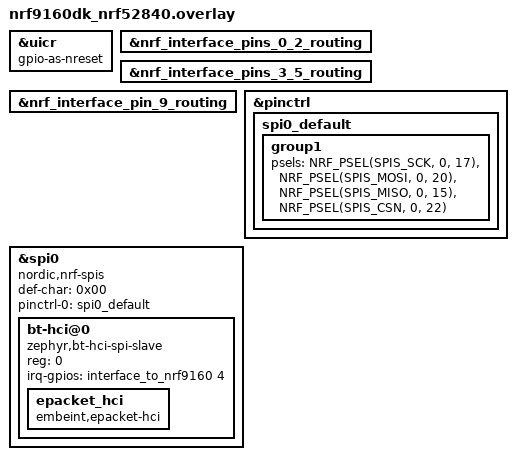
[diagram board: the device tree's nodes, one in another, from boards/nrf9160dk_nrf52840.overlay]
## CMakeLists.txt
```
# SPDX-License-Identifier: Apache-2.0

cmake_minimum_required(VERSION 3.20.0)
find_package(Zephyr REQUIRED HINTS $ENV{ZEPHYR_BASE})
project(hci_spi)

FILE(GLOB app_sources src/*.c)
target_sources(app PRIVATE ${app_sources})
```

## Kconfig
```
# Firmware update values

config INFUSE_APPLICATION_ID
	hex "Unique application identifier"
	default 0xB7000001

configdefault IMG_MANAGER
	default y

configdefault INFUSE_CPATCH
	default y if BOOTLOADER_MCUBOOT

config HEAP_MEM_POOL_ADD_SIZE_HCI_IPC
	int "Heap size required by IPC library"
	depends on DT_HAS_ZEPHYR_BT_HCI_IPC_ENABLED
	default 4096

# Reduced RAM footprint on memory constrained platforms
configdefault BT_MAX_CONN
	default 4 if SOC_NRF54L05
	default 4 if SOC_NRF52832
	default 8 if SOC_NRF52833
	default 16

configdefault BT_EXT_ADV_MAX_ADV_SET
	default 2 if SOC_NRF54L05
	default 4 if SOC_NRF52832
	default 6

# Softdevice default values

configdefault BT_CTLR_SDC_PERIPHERAL_COUNT
	default 3

configdefault BT_CTLR_SDC_SCAN_BUFFER_COUNT
	default 5

configdefault BT_CTLR_SDC_TX_PACKET_COUNT
	default 5

configdefault BT_CTLR_SDC_RX_PACKET_COUNT
	default 5

# No logging or console output on ROM constrained platforms
if SOC_NRF54L05

configdefault LOG
	default n

configdefault PRINTK
	default n

configdefault BOOT_BANNER
	default n

configdefault EARLY_CONSOLE
	default n

configdefault STDOUT_CONSOLE
	default n

endif # SOC_NRF54L05

# Channel Sounding (only available on SoCs with radio support)
configdefault BT_CTLR_CHANNEL_SOUNDING
	default y

configdefault BT_CTLR_CHANNEL_SOUNDING_TEST
	default n if SOC_NRF54L05

source "Kconfig.zephyr"
```

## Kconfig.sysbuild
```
# ECDSA-P256 verification is smaller than RSA-2048 in MCUboot
choice BOOT_SIGNATURE_TYPE
	default BOOT_SIGNATURE_TYPE_ECDSA_P256 if "$(BOARD_QUALIFIERS)" = "nrf54l05/cpuapp"
endchoice

config INFUSE_MCUBOOT_MULTITHREADING
	default n if "$(BOARD_QUALIFIERS)" = "nrf54l05/cpuapp"

source "share/sysbuild/Kconfig"
```

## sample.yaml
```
sample:
  description: Allows Zephyr to provide Bluetooth connectivity via SPI.
  name: Bluetooth HCI SPI
common:
  tags:
    - app
    - cpatch
    - epacket
    - kv_store
    - rpc
  harness: bluetooth
  filter: dt_compat_enabled("zephyr,bt-hci-spi-slave")
  integration_platforms:
    - auroch@1.0.0/nrf54l15/cpuapp
    - tauro2/nrf54l15/cpuapp
    - tauro/nrf52840
  platform_exclude:
    - nrf9160dk@0.7.0/nrf52840
tests:
  sample.bluetooth.hci_spi:
    sysbuild: false
    integration_platforms:
      - thingy91x/nrf5340/cpuapp
  sample.bluetooth.hci_spi.sysbuild:
    sysbuild: true
    integration_platforms:
      - thingy91x/nrf5340/cpuapp
      - nrf54l15dk/nrf54l05/cpuapp
  sample.bluetooth.hci_spi.infuse:
    filter: dt_compat_enabled("zephyr,bt-hci-spi-slave") and not CONFIG_SOC_NRF5340_CPUAPP
    required_snippets:
      - infuse-bt-ctlr
    sysbuild: false
  sample.bluetooth.hci_spi.sysbuild.infuse:
    filter: dt_compat_enabled("zephyr,bt-hci-spi-slave") and not CONFIG_SOC_NRF5340_CPUAPP
    required_snippets:
      - infuse-bt-ctlr
    sysbuild: true
```

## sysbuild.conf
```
SB_CONFIG_INFUSE_INTEGRATION=y
SB_CONFIG_INFUSE_INTEGRATION_BT_CTLR=y
```

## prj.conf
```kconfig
CONFIG_GPIO=y
CONFIG_SPI=y
CONFIG_SPI_PERIPHERAL=y
CONFIG_MAIN_STACK_SIZE=1024
CONFIG_BT=y
CONFIG_BT_HCI_RAW=y

# Flash operations for DFU
CONFIG_FLASH=y
CONFIG_FLASH_MAP=y
CONFIG_STREAM_FLASH=y
CONFIG_CRC=y

# Infuse-IoT Bluetooth defaults
CONFIG_INFUSE_SDK_BLUETOOTH=y

# RPC commands
CONFIG_INFUSE_RPC=y
CONFIG_INFUSE_RPC_COMMAND_APPLICATION_INFO=y
CONFIG_INFUSE_RPC_COMMAND_FILE_WRITE_BASIC=y

# Infuse-IoT ePacket
CONFIG_NET_BUF_POOL_USAGE=y
CONFIG_EPACKET=y
CONFIG_EPACKET_BUFFERS_RX=5

# Output the .lst file
CONFIG_OUTPUT_DISASSEMBLY=y
```

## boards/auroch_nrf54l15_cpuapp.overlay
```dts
#include "nordic_sdc.dtsi"
```

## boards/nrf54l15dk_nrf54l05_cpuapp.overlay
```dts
#include "nordic_sdc.dtsi"

&pinctrl {
	spi21_default: spi21_default {
		group1 {
			psels = <NRF_PSEL(SPIS_SCK, 1, 11)>,
				<NRF_PSEL(SPIS_MOSI, 1, 12)>,
				<NRF_PSEL(SPIS_MISO, 1, 15)>,
				<NRF_PSEL(SPIS_CSN, 1, 16)>;
		};
	};
};

&spi21 {
	compatible = "nordic,nrf-spis";
	status = "okay";
	def-char = <0x00>;
	pinctrl-0 = <&spi21_default>;
	pinctrl-names = "default";
	/delete-property/rx-delay-supported;
	/delete-property/rx-delay;

	wake-gpios = <&gpio0 2 GPIO_ACTIVE_HIGH>;

	hci_spi: bt-hci@0 {
		compatible = "zephyr,bt-hci-spi-slave";
		reg = <0>;
		irq-gpios = <&gpio0 3 GPIO_ACTIVE_HIGH>;
	};
};

/* External flash is unused */
&mx25r64 {
	status = "disabled";
};
```

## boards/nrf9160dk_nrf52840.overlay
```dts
/*
 * Copyright (c) 2024 Embeint Holdings Pty Ltd
 *
 * SPDX-License-Identifier: Apache-2.0
 */

&uicr {
	gpio-as-nreset;
};

/* Route pins through for SPI */
&nrf_interface_pins_0_2_routing {
	status = "okay";
};
&nrf_interface_pins_3_5_routing {
	status = "okay";
};
&nrf_interface_pin_9_routing {
	status = "okay";
};

&pinctrl {
	/* nRF9160 interface pins */
	spi0_default: spi0_default {
		group1 {
			psels = <NRF_PSEL(SPIS_SCK, 0, 17)>,
				<NRF_PSEL(SPIS_MOSI, 0, 20)>,
				<NRF_PSEL(SPIS_MISO, 0, 15)>,
				<NRF_PSEL(SPIS_CSN, 0, 22)>;
		};
	};
};

&spi0 {
	compatible = "nordic,nrf-spis";
	status = "okay";
	def-char = <0x00>;
	pinctrl-0 = <&spi0_default>;
	pinctrl-names = "default";

	bt-hci@0 {
		compatible = "zephyr,bt-hci-spi-slave";
		reg = <0>;
		irq-gpios = <&interface_to_nrf9160 4 GPIO_ACTIVE_HIGH>;
		epacket_hci: epacket_hci {
			compatible = "embeint,epacket-hci";
		};
	};
};

#include "nordic_sdc.dtsi"
```

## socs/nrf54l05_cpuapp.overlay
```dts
/*
 * Maximise image slot sizes on the nRF54L05 (500 kB RRAM)
 *
 * Reduced bootloader partition and no storage partition.
 * The secondary slot is one sector larger, as required by MCUboot swap-using-offset.
 *
 * Applied to both the application and MCUboot (see sysbuild.cmake).
 */

&cpuapp_rram {
	/delete-node/ partitions;

	partitions {
		#address-cells = <1>;
		#size-cells = <1>;

		boot_partition: partition@0 {
			compatible = "zephyr,mapped-partition";
			label = "mcuboot";
			reg = <0x0 DT_SIZE_K(24)>;
		};
		slot0_partition: partition@6000 {
			compatible = "zephyr,mapped-partition";
			label = "image-0";
			reg = <0x6000 DT_SIZE_K(236)>;
		};
		slot1_partition: partition@41000 {
			compatible = "zephyr,mapped-partition";
			label = "image-1";
			reg = <0x41000 DT_SIZE_K(240)>;
		};
	};
};
```

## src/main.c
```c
/*
 * Copyright (c) 2017 Linaro Limited
 * Copyright (c) 2016 Nordic Semiconductor ASA
 * Copyright (c) 2015-2016 Intel Corporation
 *
 * SPDX-License-Identifier: Apache-2.0
 */

#include <errno.h>
#include <stddef.h>
#include <stdio.h>

#include <zephyr/kernel.h>
#include <zephyr/sys/byteorder.h>
#include <zephyr/logging/log.h>
#include <zephyr/debug/stack.h>

#include <zephyr/device.h>
#include <zephyr/init.h>
#include <zephyr/drivers/gpio.h>
#include <zephyr/drivers/spi.h>
#include <zephyr/dfu/mcuboot.h>

#include <zephyr/net_buf.h>
#include <zephyr/bluetooth/bluetooth.h>
#include <zephyr/bluetooth/l2cap.h>
#include <zephyr/bluetooth/hci.h>
#include <zephyr/bluetooth/buf.h>
#include <zephyr/bluetooth/hci_raw.h>

#define LOG_MODULE_NAME hci_spi
LOG_MODULE_REGISTER(LOG_MODULE_NAME);

#define HCI_CMD 0x01
#define HCI_ACL 0x02
#define HCI_SCO 0x03
#define HCI_EVT 0x04

/* Special Values */
#define SPI_WRITE    0x0A
#define SPI_READ     0x0B
#define READY_NOW    0x02
#define SANITY_CHECK 0x02

/* Offsets */
#define STATUS_HEADER_READY  0
#define STATUS_HEADER_TOREAD 3

#define PACKET_TYPE          0
#define EVT_BLUE_INITIALIZED 0x01

/* Needs to be aligned with the SPI master buffer size */
#define SPI_MAX_MSG_LEN 255

static uint8_t rxmsg[SPI_MAX_MSG_LEN] __aligned(4);
static struct spi_buf rx;
const static struct spi_buf_set rx_bufs = {
	.buffers = &rx,
	.count = 1,
};

static uint8_t txmsg[SPI_MAX_MSG_LEN] __aligned(4);
static struct spi_buf tx;
const static struct spi_buf_set tx_bufs = {
	.buffers = &tx,
	.count = 1,
};

/* HCI buffer pools */
#define CMD_BUF_SIZE BT_BUF_RX_SIZE

/*
 * This finds an arbitrary node with compatible
 * "zephyr,bt-hci-spi-slave". There should just be one in the
 * devicetree.
 *
 * If for some reason you have more than one of these in your
 * devicetree, replace this macro definition to pick one, e.g. using
 * DT_NODELABEL().
 */
#define HCI_SPI_NODE DT_COMPAT_GET_ANY_STATUS_OKAY(zephyr_bt_hci_spi_slave)

/*
 * This is the SPI bus controller device used to exchange data with
 * the SPI-based BT controller.
 */
static const struct device *const spi_hci_dev = DEVICE_DT_GET(DT_BUS(HCI_SPI_NODE));
static struct spi_config spi_cfg = {
	.operation = SPI_WORD_SET(8) | SPI_OP_MODE_PERIPHERAL,
};

/*
 * The GPIO used to send interrupts to the host,
 * configured in the 'irq-gpios' property in HCI_SPI_NODE.
 */
static const struct gpio_dt_spec irq = GPIO_DT_SPEC_GET(HCI_SPI_NODE, irq_gpios);

static K_THREAD_STACK_DEFINE(bt_tx_thread_stack, CONFIG_BT_HCI_TX_STACK_SIZE);
static struct k_thread bt_tx_thread_data;

static K_SEM_DEFINE(sem_spi_rx, 0, 1);
static K_SEM_DEFINE(sem_spi_tx, 0, 1);

static inline int spi_send(struct net_buf *buf)
{
	uint8_t header_master[5] = {0};
	uint8_t header_slave[5] = {READY_NOW, SANITY_CHECK, 0x00, 0x00, 0x00};
	int ret;

	LOG_DBG("buf %p type %u len %u", buf, buf->data[0], buf->len);

	if (buf->len > SPI_MAX_MSG_LEN) {
		LOG_ERR("TX message too long");
		net_buf_unref(buf);
		return -EINVAL;
	}
	header_slave[STATUS_HEADER_TOREAD] = buf->len;

	gpio_pin_set(irq.port, irq.pin, 1);

	/* Coordinate transfer lock with the spi rx thread */
	k_sem_take(&sem_spi_tx, K_FOREVER);

	tx.buf = header_slave;
	tx.len = 5;
	rx.buf = header_master;
	rx.len = 5;
	do {
		ret = spi_transceive(spi_hci_dev, &spi_cfg, &tx_bufs, &rx_bufs);
		if (ret < 0) {
			LOG_ERR("SPI transceive error: %d", ret);
		}
	} while (header_master[STATUS_HEADER_READY] != SPI_READ);

	tx.buf = buf->data;
	tx.len = buf->len;

	ret = spi_write(spi_hci_dev, &spi_cfg, &tx_bufs);
	if (ret < 0) {
		LOG_ERR("SPI transceive error: %d", ret);
	}
	net_buf_unref(buf);

	gpio_pin_set(irq.port, irq.pin, 0);
	k_sem_give(&sem_spi_rx);

	return 0;
}

static void bt_tx_thread(void *p1, void *p2, void *p3)
{
	uint8_t header_master[5] __aligned(4);
	uint8_t header_slave[5] __aligned(4) = {READY_NOW, SANITY_CHECK, 0x00, 0x00, 0x00};
	struct net_buf *buf = NULL;

	union {
		struct bt_hci_cmd_hdr *cmd_hdr;
		struct bt_hci_acl_hdr *acl_hdr;
	} hci_hdr;
	hci_hdr.cmd_hdr = (struct bt_hci_cmd_hdr *)&rxmsg[1];
	int cnt = 0;
	int ret;

	ARG_UNUSED(p1);
	ARG_UNUSED(p2);
	ARG_UNUSED(p3);
	ARG_UNUSED(cnt);
	(void)memset(txmsg, 0xFF, SPI_MAX_MSG_LEN);

	while (1) {
		tx.buf = header_slave;
		tx.len = 5;
		rx.buf = header_master;
		rx.len = 5;

		do {
			ret = spi_transceive(spi_hci_dev, &spi_cfg, &tx_bufs, &rx_bufs);
			if (ret < 0) {
				LOG_ERR("SPI transceive error: %d", ret);
			}
		} while ((header_master[STATUS_HEADER_READY] != SPI_READ) &&
			 (header_master[STATUS_HEADER_READY] != SPI_WRITE));

		if (header_master[STATUS_HEADER_READY] == SPI_READ) {
			/* Unblock the spi tx thread and wait for it */
			k_sem_give(&sem_spi_tx);
			k_sem_take(&sem_spi_rx, K_FOREVER);
			continue;
		}

		tx.buf = txmsg;
		tx.len = SPI_MAX_MSG_LEN;
		rx.buf = rxmsg;
		rx.len = SPI_MAX_MSG_LEN;

		/* Receiving data from the SPI Host */
		ret = spi_transceive(spi_hci_dev, &spi_cfg, &tx_bufs, &rx_bufs);
		if (ret < 0) {
			LOG_ERR("SPI transceive error: %d", ret);
			continue;
		}

		switch (rxmsg[PACKET_TYPE]) {
		case HCI_CMD:
			buf = bt_buf_get_tx(BT_BUF_CMD, K_NO_WAIT, hci_hdr.cmd_hdr,
					    sizeof(*hci_hdr.cmd_hdr));
			if (buf) {
				net_buf_add_mem(buf, &rxmsg[4], hci_hdr.cmd_hdr->param_len);
			} else {
				LOG_ERR("No available command buffers!");
				continue;
			}
			break;
		case HCI_ACL:
			buf = bt_buf_get_tx(BT_BUF_ACL_OUT, K_NO_WAIT, hci_hdr.acl_hdr,
					    sizeof(*hci_hdr.acl_hdr));
			if (buf) {
				net_buf_add_mem(buf, &rxmsg[5],
						sys_le16_to_cpu(hci_hdr.acl_hdr->len));
			} else {
				LOG_ERR("No available ACL buffers!");
				continue;
			}
			break;
		default:
			LOG_ERR("Unknown BT HCI buf type");
			continue;
		}

		LOG_DBG("buf %p type %u len %u", buf, buf->data[0], buf->len);

		ret = bt_send(buf);
		if (ret) {
			LOG_ERR("Unable to send (ret %d)", ret);
			net_buf_unref(buf);
		}

#ifdef CONFIG_MCUBOOT_IMG_MANAGER
		if (cnt++ == 0) {
			/* We've received a good packet from the BT host, mark image as confirmed */
			boot_write_img_confirmed();
		}
#endif /* CONFIG_MCUBOOT_IMG_MANAGER */

		/* Make sure other threads get a chance to run */
		k_yield();
	}
}

static int hci_spi_init(void)
{

	LOG_DBG("");

	if (!device_is_ready(spi_hci_dev)) {
		LOG_ERR("SPI bus %s is not ready", spi_hci_dev->name);
		return -EINVAL;
	}

	if (!gpio_is_ready_dt(&irq)) {
		LOG_ERR("IRQ GPIO port %s is not ready", irq.port->name);
		return -EINVAL;
	}
	gpio_pin_configure_dt(&irq, GPIO_OUTPUT_INACTIVE);

	return 0;
}

SYS_INIT(hci_spi_init, APPLICATION, CONFIG_KERNEL_INIT_PRIORITY_DEVICE);

int main(void)
{
	static K_FIFO_DEFINE(rx_queue);
	struct bt_hci_evt_hdr *evt_hdr;
	struct net_buf *buf;
	k_tid_t tx_id;
	int err;

	LOG_DBG("Start");

	err = bt_enable_raw(&rx_queue);
	if (err) {
		LOG_ERR("bt_enable_raw: %d; aborting", err);
		return 0;
	}

	/* Spawn the TX thread, which feeds cmds and data to the controller */
	tx_id = k_thread_create(&bt_tx_thread_data, bt_tx_thread_stack,
				K_THREAD_STACK_SIZEOF(bt_tx_thread_stack), bt_tx_thread, NULL, NULL,
				NULL, K_PRIO_COOP(7), 0, K_NO_WAIT);
	k_thread_name_set(&bt_tx_thread_data, "bt_tx_thread");

	/* Send a vendor event to announce that the slave is initialized */
	buf = bt_buf_get_rx(BT_BUF_EVT, K_FOREVER);
	evt_hdr = net_buf_add(buf, sizeof(*evt_hdr));
	evt_hdr->evt = BT_HCI_EVT_VENDOR;
	evt_hdr->len = 2U;
	net_buf_add_le16(buf, EVT_BLUE_INITIALIZED);
	err = spi_send(buf);
	if (err) {
		LOG_ERR("can't send initialization event; aborting");
		k_thread_abort(tx_id);
		return 0;
	}

	while (1) {
		buf = k_fifo_get(&rx_queue, K_FOREVER);
		err = spi_send(buf);
		if (err) {
			LOG_ERR("Failed to send");
		}
		/* Ensure that the IRQ line is de-asserted for some minimum
		 * duration between buffers, so that the HCI controller has
		 * time to observe the edge.
		 */
		k_sleep(K_TICKS(1));
	}
	return 0;
}

/* ePacket stubs required for the HCI interface as INFUSE_SECURITY is not enabled */
uint32_t infuse_security_device_key_identifier(void)
{
	return 0;
}

uint32_t infuse_security_network_key_identifier(void)
{
	return 0;
}
```
